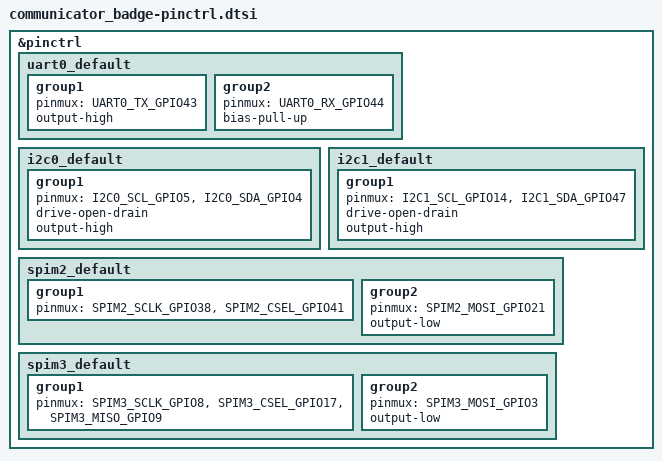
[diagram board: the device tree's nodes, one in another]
/*
 * SPDX-FileCopyrightText: Copyright The Zephyr Project Contributors
 * SPDX-License-Identifier: Apache-2.0
 */

#include <zephyr/dt-bindings/pinctrl/esp-pinctrl-common.h>
#include <zephyr/dt-bindings/pinctrl/esp32s3-pinctrl.h>
#include <zephyr/dt-bindings/pinctrl/esp32s3-gpio-sigmap.h>

&pinctrl {
	uart0_default: uart0_default {
		group1 {
			pinmux = <UART0_TX_GPIO43>;
			output-high;
		};

		group2 {
			pinmux = <UART0_RX_GPIO44>;
			bias-pull-up;
		};
	};

	/* SAO header, external pull-ups */
	i2c0_default: i2c0_default {
		group1 {
			pinmux = <I2C0_SCL_GPIO5>, <I2C0_SDA_GPIO4>;
			drive-open-drain;
			output-high;
		};
	};

	/* Keyboard controller, external pull-ups */
	i2c1_default: i2c1_default {
		group1 {
			pinmux = <I2C1_SCL_GPIO14>, <I2C1_SDA_GPIO47>;
			drive-open-drain;
			output-high;
		};
	};

	/* Display, write-only */
	spim2_default: spim2_default {
		group1 {
			pinmux = <SPIM2_SCLK_GPIO38>, <SPIM2_CSEL_GPIO41>;
		};

		group2 {
			pinmux = <SPIM2_MOSI_GPIO21>;
			output-low;
		};
	};

	/* LoRa module */
	spim3_default: spim3_default {
		group1 {
			pinmux = <SPIM3_SCLK_GPIO8>, <SPIM3_CSEL_GPIO17>, <SPIM3_MISO_GPIO9>;
		};

		group2 {
			pinmux = <SPIM3_MOSI_GPIO3>;
			output-low;
		};
	};
};
